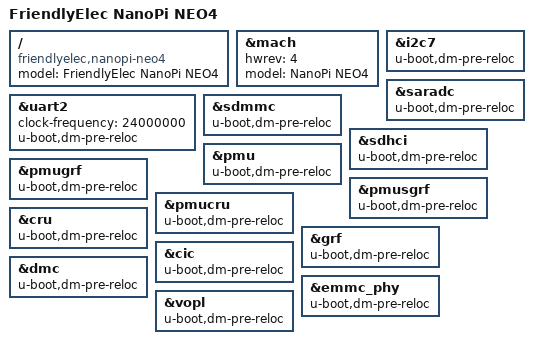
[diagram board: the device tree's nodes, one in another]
/*
 * Copyright (c) 2018 FriendlyElec Computer Tech. Co., Ltd.
 * (http://www.friendlyarm.com)
 *
 * This program is free software; you can redistribute it and/or
 * modify it under the terms of the GNU General Public License
 * as published by the Free Software Foundation; either version 2
 * of the License, or (at your option) any later version.
 *
 * This program is distributed in the hope that it will be useful,
 * but WITHOUT ANY WARRANTY; without even the implied warranty of
 * MERCHANTABILITY or FITNESS FOR A PARTICULAR PURPOSE.  See the
 * GNU General Public License for more details.
 *
 * You should have received a copy of the GNU General Public License
 * along with this program.  If not, see <http://www.gnu.org/licenses/>.
 */

/dts-v1/;
#include "rk3399-nanopi4-common.dtsi"

/ {
	model = "FriendlyElec NanoPi NEO4";
	compatible = "friendlyelec,nanopi-neo4", "rockchip,rk3399";
};

&mach {
	hwrev = <4>;
	model = "NanoPi NEO4";
};

&i2c7 {
	status = "okay";
	u-boot,dm-pre-reloc;
};

&uart2 {
	clock-frequency = <24000000>;
	u-boot,dm-pre-reloc;
};

&saradc {
	u-boot,dm-pre-reloc;
	status = "okay";
};

&sdmmc {
	u-boot,dm-pre-reloc;
};

&sdhci {
	u-boot,dm-pre-reloc;
};

&pmu {
	u-boot,dm-pre-reloc;
};

&pmugrf {
	u-boot,dm-pre-reloc;
};

&pmusgrf {
	u-boot,dm-pre-reloc;
};

&pmucru {
	u-boot,dm-pre-reloc;
};

&cru {
	u-boot,dm-pre-reloc;
};

&grf {
	u-boot,dm-pre-reloc;
};

&cic {
	u-boot,dm-pre-reloc;
};

&dmc {
	u-boot,dm-pre-reloc;
};

&emmc_phy {
	u-boot,dm-pre-reloc;
};

&vopl {
	u-boot,dm-pre-reloc;
};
